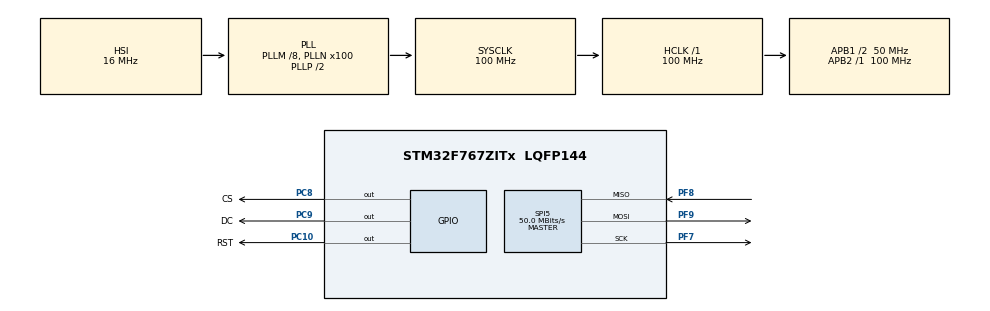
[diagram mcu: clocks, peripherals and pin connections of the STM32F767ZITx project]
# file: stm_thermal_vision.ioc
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Mcu.Family=STM32F7
Mcu.Name=STM32F767ZITx
Mcu.Package=LQFP144
NVIC.PriorityGroup=NVIC_PRIORITYGROUP_4
PC10.GPIO_Label=RST
PC10.Signal=GPIO_Output
PC8.GPIO_Label=CS
PC8.Signal=GPIO_Output
PC9.GPIO_Label=DC
PC9.Signal=GPIO_Output
PF7.Mode=Full_Duplex_Master
PF7.Signal=SPI5_SCK
PF8.Mode=Full_Duplex_Master
PF8.Signal=SPI5_MISO
PF9.Mode=Full_Duplex_Master
PF9.Signal=SPI5_MOSI
ProjectManager.HeapSize=0x200
ProjectManager.StackSize=0x400
ProjectManager.TargetToolchain=MDK-ARM V5.27
RCC.AHBFreq_Value=100000000
RCC.APB1CLKDivider=RCC_HCLK_DIV2
RCC.APB1Freq_Value=50000000
RCC.APB1TimFreq_Value=100000000
RCC.APB2Freq_Value=100000000
RCC.APB2TimFreq_Value=100000000
RCC.CortexFreq_Value=100000000
RCC.HCLKFreq_Value=100000000
RCC.HSE_VALUE=25000000
RCC.HSI_VALUE=16000000
RCC.LSE_VALUE=32768
RCC.PLLM=8
RCC.PLLN=100
RCC.PLLQ=5
RCC.SYSCLKFreq_VALUE=100000000
RCC.SYSCLKSource=RCC_SYSCLKSOURCE_PLLCLK
RCC.USBFreq_Value=40000000
RCC.VCOOutputFreq_Value=200000000
SPI5.CalculateBaudRate=50.0 MBits/s
SPI5.DataSize=SPI_DATASIZE_8BIT
SPI5.Direction=SPI_DIRECTION_2LINES
SPI5.Mode=SPI_MODE_MASTER
SPI5.NSSPMode=SPI_NSS_PULSE_DISABLE
SPI5.VirtualType=VM_MASTER
board=custom

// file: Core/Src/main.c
/* USER CODE BEGIN Header */
/**
  ******************************************************************************
  * @file           : main.c
  * @brief          : Main program body
  ******************************************************************************
  * @attention
  *
  * <h2><center>&copy; Copyright (c) 2020 STMicroelectronics.
  * All rights reserved.</center></h2>
  *
  * This software component is licensed by ST under BSD 3-Clause license,
  * the "License"; You may not use this file except in compliance with the
  * License. You may obtain a copy of the License at:
  *                        opensource.org/licenses/BSD-3-Clause
  *
  ******************************************************************************
  */
/* USER CODE END Header */
#include "main.h"

/* USER CODE BEGIN Includes */
#include "ILI9341_GFX.h"

/* USER CODE END Includes */

SPI_HandleTypeDef hspi5;

void SystemClock_Config(void);
static void MX_GPIO_Init(void);
static void MX_SPI5_Init(void);

int main(void)
{

  /* MCU Configuration--------------------------------------------------------*/

  /* Reset of all peripherals, Initializes the Flash interface and the Systick. */
  HAL_Init();

  /* Configure the system clock */
  SystemClock_Config();

  /* Initialize all configured peripherals */
  MX_GPIO_Init();
  MX_SPI5_Init();
  /* USER CODE BEGIN 2 */
	ILI9341_Init();
		ILI9341_Set_Rotation(SCREEN_HORIZONTAL_2);

  /* USER CODE END 2 */

  /* Infinite loop */
  /* USER CODE BEGIN WHILE */
  while (1)
  {

		HAL_Delay(1000);

    /* USER CODE END WHILE */

  }
}

void SystemClock_Config(void)
{
  RCC_OscInitTypeDef RCC_OscInitStruct = {0};
  RCC_ClkInitTypeDef RCC_ClkInitStruct = {0};

  /** Configure the main internal regulator output voltage
  */
  __HAL_RCC_PWR_CLK_ENABLE();
  __HAL_PWR_VOLTAGESCALING_CONFIG(PWR_REGULATOR_VOLTAGE_SCALE3);
  /** Initializes the RCC Oscillators according to the specified parameters
  * in the RCC_OscInitTypeDef structure.
  */
  RCC_OscInitStruct.OscillatorType = RCC_OSCILLATORTYPE_HSI;
  RCC_OscInitStruct.HSIState = RCC_HSI_ON;
  RCC_OscInitStruct.HSICalibrationValue = RCC_HSICALIBRATION_DEFAULT;
  RCC_OscInitStruct.PLL.PLLState = RCC_PLL_ON;
  RCC_OscInitStruct.PLL.PLLSource = RCC_PLLSOURCE_HSI;
  RCC_OscInitStruct.PLL.PLLM = 8;
  RCC_OscInitStruct.PLL.PLLN = 100;
  RCC_OscInitStruct.PLL.PLLP = RCC_PLLP_DIV2;
  RCC_OscInitStruct.PLL.PLLQ = 5;
  if (HAL_RCC_OscConfig(&RCC_OscInitStruct) != HAL_OK)
  {
    Error_Handler();
  }
  /** Activate the Over-Drive mode
  */
  if (HAL_PWREx_EnableOverDrive() != HAL_OK)
  {
    Error_Handler();
  }
  /** Initializes the CPU, AHB and APB buses clocks
  */
  RCC_ClkInitStruct.ClockType = RCC_CLOCKTYPE_HCLK|RCC_CLOCKTYPE_SYSCLK
                              |RCC_CLOCKTYPE_PCLK1|RCC_CLOCKTYPE_PCLK2;
  RCC_ClkInitStruct.SYSCLKSource = RCC_SYSCLKSOURCE_PLLCLK;
  RCC_ClkInitStruct.AHBCLKDivider = RCC_SYSCLK_DIV1;
  RCC_ClkInitStruct.APB1CLKDivider = RCC_HCLK_DIV2;
  RCC_ClkInitStruct.APB2CLKDivider = RCC_HCLK_DIV1;

  if (HAL_RCC_ClockConfig(&RCC_ClkInitStruct, FLASH_LATENCY_3) != HAL_OK)
  {
    Error_Handler();
  }
}

static void MX_SPI5_Init(void)
{

  /* SPI5 parameter configuration*/
  hspi5.Instance = SPI5;
  hspi5.Init.Mode = SPI_MODE_MASTER;
  hspi5.Init.Direction = SPI_DIRECTION_2LINES;
  hspi5.Init.DataSize = SPI_DATASIZE_8BIT;
  hspi5.Init.CLKPolarity = SPI_POLARITY_LOW;
  hspi5.Init.CLKPhase = SPI_PHASE_1EDGE;
  hspi5.Init.NSS = SPI_NSS_SOFT;
  hspi5.Init.BaudRatePrescaler = SPI_BAUDRATEPRESCALER_2;
  hspi5.Init.FirstBit = SPI_FIRSTBIT_MSB;
  hspi5.Init.TIMode = SPI_TIMODE_DISABLE;
  hspi5.Init.CRCCalculation = SPI_CRCCALCULATION_DISABLE;
  hspi5.Init.CRCPolynomial = 7;
  hspi5.Init.CRCLength = SPI_CRC_LENGTH_DATASIZE;
  hspi5.Init.NSSPMode = SPI_NSS_PULSE_DISABLE;
  if (HAL_SPI_Init(&hspi5) != HAL_OK)
  {
    Error_Handler();
  }

}

static void MX_GPIO_Init(void)
{
  GPIO_InitTypeDef GPIO_InitStruct = {0};

  /* GPIO Ports Clock Enable */
  __HAL_RCC_GPIOF_CLK_ENABLE();
  __HAL_RCC_GPIOC_CLK_ENABLE();

  /*Configure GPIO pin Output Level */
  HAL_GPIO_WritePin(GPIOC, CS_Pin|DC_Pin|RST_Pin, GPIO_PIN_RESET);

  /*Configure GPIO pins : CS_Pin DC_Pin RST_Pin */
  GPIO_InitStruct.Pin = CS_Pin|DC_Pin|RST_Pin;
  GPIO_InitStruct.Mode = GPIO_MODE_OUTPUT_PP;
  GPIO_InitStruct.Pull = GPIO_NOPULL;
  GPIO_InitStruct.Speed = GPIO_SPEED_FREQ_LOW;
  HAL_GPIO_Init(GPIOC, &GPIO_InitStruct);

}

void Error_Handler(void)
{
}

/************************ (C) COPYRIGHT STMicroelectronics *****END OF FILE****/
